# PRM_PER register map
Vendor: Texas Instruments
Peripheral module from a debugger description file (folder am437x).
Registers are 32-bit, access per field, no defined reset value unless marked. A register's access mark holds for its fields unless they carry their own. Offsets are as the file gives them; lines under a group give offsets from that group; [hi:lo] are bit positions; {n}, {i} and the like mark numbered series; 'fields as' and 'values as' point back to an identical list; <NAME> marks a mode.

## PRM_PER
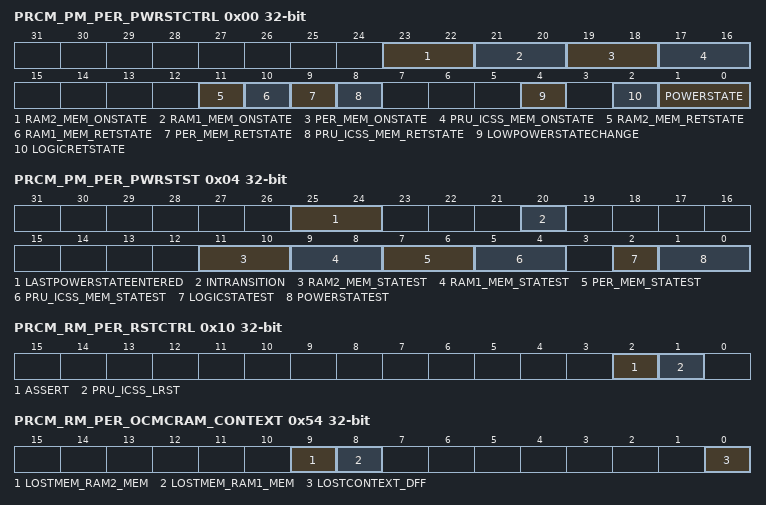
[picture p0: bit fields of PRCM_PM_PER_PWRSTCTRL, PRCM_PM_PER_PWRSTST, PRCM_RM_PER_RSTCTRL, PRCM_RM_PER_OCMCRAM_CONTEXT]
0x00 PRCM_PM_PER_PWRSTCTRL — Controls the power state of PER power domain
  [23:22] RAM2_MEM_ONSTATE ro — OCMC RAM Group 2 (Last 192KB) memory on state
    3=en_1_0x3 (Memory is ON)
  [21:20] RAM1_MEM_ONSTATE ro — OCMC RAM Group 1 (First 64KB) memory on state
    3=en_1_0x3 (Memory is ON)
  [19:18] PER_MEM_ONSTATE ro — Other memories in PER Domain ON state
    3=en_1_0x3 (Memory is ON)
  [17:16] PRU_ICSS_MEM_ONSTATE ro — PRU-ICSS memory ON state
    3=en_1_0x3 (Memory is ON)
  [11] RAM2_MEM_RETSTATE rw — RAM2_MEM[OCMC RAM Group 2 (Last 192KB)] bank state when domain is retention.
    1=en_2_0x1 (Memory is retained when domain is in RETENTION state.); 0=en_1_0x0 (Memory is off when the domain is in the RETENTION state.)
  [10] RAM1_MEM_RETSTATE rw — RAM1_MEM[OCMC RAM Group 1 (First 64KB)] bank state when domain is retention.
    values as RAM2_MEM_RETSTATE
  [9] PER_MEM_RETSTATE rw — PER_MEM bank state when domain is retention.
    values as RAM2_MEM_RETSTATE
  [8] PRU_ICSS_MEM_RETSTATE rw — PRU-ICSS bank state when domain is retention.
    values as RAM2_MEM_RETSTATE
  [4] LOWPOWERSTATECHANGE rw — Power state change request when domain has already performed a sleep transition. [[br]]Allows going into deeper low power state without waking up the power domain.
    1=en_2_0x1 (Request a low power state change. This bit is automatically cleared when the power state is effectively changed or when power state is ON.); 0=en_1_0x0 (Do not request a low power state change.)
  [2] LOGICRETSTATE rw — Logic state when power domain is RETENTION
    1=en_2_0x1 (Whole logic is retained when domain is in RETENTION state.); 0=en_1_0x0 (Only retention registers are retained and remaing logic is off when the domain is in RETENTION state.)
  [1:0] POWERSTATE rw — PER domain power state control
    3=en_4_0x3 (ON State); 2=en_3_0x2 (RESERVED); 1=en_2_0x1 (RETENTION state); 0=en_1_0x0 (OFF State)
0x04 PRCM_PM_PER_PWRSTST — This register provides a status on the current PER power domain state. [warm reset insensitive]
  [25:24] LASTPOWERSTATEENTERED rw — Last low power state entered. [[br]]Set to 0x3 upon write of the same only. [[br]]This register is intended for debug purpose only.
    3=en_4_0x3 (Power domain was previously ON-ACTIVE); 2=en_3_0x2 (Power domain was previously ON-INACTIVE); 1=en_2_0x1 (Power domain was previously in RETENTION); 0=en_1_0x0 (Power domain was previously OFF)
  [20] INTRANSITION ro — Domain transition status
    1=en_2_0x1 (Power domain transition is in progress.); 0=en_1_0x0 (No on-going transition on power domain)
  [11:10] RAM2_MEM_STATEST ro — OCMC RAM Group 1 (Last 192KB) memory state status
    3=en_4_0x3 (Memory is ON); 2=en_3_0x2 (Reserved); 1=en_2_0x1 (Memory is in RETENTION.); 0=en_1_0x0 (Memory is OFF)
  [9:8] RAM1_MEM_STATEST ro — OCMC RAM Group 1 (First 64KB) memory state status
    values as RAM2_MEM_STATEST
  [7:6] PER_MEM_STATEST ro — PER domain memory state status
    values as RAM2_MEM_STATEST
  [5:4] PRU_ICSS_MEM_STATEST ro — PRU-ICSS memory state status
    values as RAM2_MEM_STATEST
  [2] LOGICSTATEST ro — Logic state status
    1=en_2_0x1 (Logic in domain is ON); 0=en_1_0x0 (Logic in domain is OFF)
  [1:0] POWERSTATEST ro — Current Power State Status
    3=en_3_0x3 (ON State); 1=en_2_0x1 (RETENTION state); 0=en_1_0x0 (OFF State)
0x10 PRCM_RM_PER_RSTCTRL — This register controls the release of the PER Domain resets.
  [2] ASSERT ro
  [1] PRU_ICSS_LRST rw — PER domain PRU-ICSS local reset control
    1=en_2_0x1 (Reset is asserted for the PRU-ICSS); 0=en_1_0x0 (Reset is cleared for the PRU-ICSS)
0x14 PRCM_RM_PER_RSTST — This register logs the different reset sources of the PER domain. Each bit is set upon release of the domain reset signal. Must be cleared by software. [warm reset insensitive]
  [0] PRU_ICSS_LRST rw — PRU-ICSS Processor software reset status.
    1=en_2_0x1 (PRU-ICSS Processor has been reset upon SW reset); 0=en_1_0x0 (No reset)
0x24 PRCM_RM_PER_L3_CONTEXT — This register contains dedicated L3 module context statuses. [warm reset insensitive]
  [0] LOSTCONTEXT_DFF rw — Specify if DFF-based context has been lost due to a previous power transition or other reset source. [[br]](set upon assertion of PER_DOM_RST signal)
    1=en_2_0x1 (Context has been lost); 0=en_1_0x0 (Context has been maintained)
0x44 PRCM_RM_PER_L3_INSTR_CONTEXT — This register contains dedicated L3_INSTR module context statuses. [warm reset insensitive]
  fields as PRCM_RM_PER_L3_CONTEXT
0x54 PRCM_RM_PER_OCMCRAM_CONTEXT — This register contains dedicated OCMCRAM module context statuses. [warm reset insensitive]
  [all] fields
    values as PRCM_RM_PER_L3_CONTEXT.LOSTCONTEXT_DFF
  [9] LOSTMEM_RAM2_MEM rw — Specify if memory-based context in RAM2_MEM memory bank has been lost due to a previous power transition or other reset source.
  [8] LOSTMEM_RAM1_MEM rw — Specify if memory-based context in RAM1_MEM memory bank has been lost due to a previous power transition or other reset source.
  [0] LOSTCONTEXT_DFF rw — Specify if DFF-based context has been lost due to a previous power transition or other reset source. [[br]](set upon assertion of PER_DOM_RST signal)
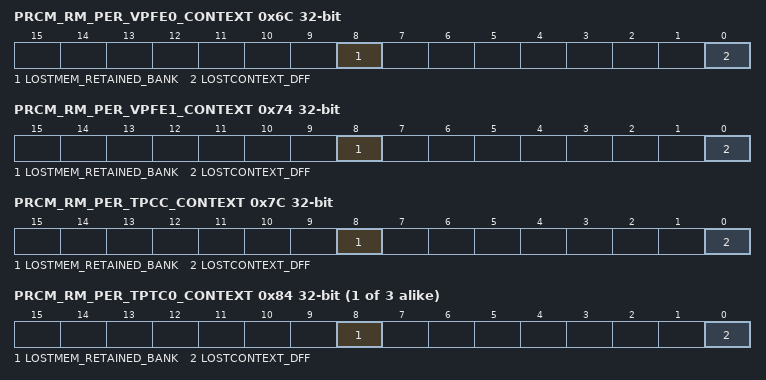
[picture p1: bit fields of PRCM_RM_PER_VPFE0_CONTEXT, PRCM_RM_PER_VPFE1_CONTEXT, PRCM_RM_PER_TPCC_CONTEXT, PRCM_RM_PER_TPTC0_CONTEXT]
0x6C PRCM_RM_PER_VPFE0_CONTEXT — This register contains dedicated VPFE0 module context statuses. [warm reset insensitive]
  [8] LOSTMEM_RETAINED_BANK rw — Specify if memory-based context in RETAINED_BANK memory bank has been lost due to a previous power transition or other reset source.
    values as PRCM_RM_PER_L3_CONTEXT.LOSTCONTEXT_DFF
  [0] LOSTCONTEXT_DFF rw — Specify if DFF-based context has been lost due to a previous power transition or other reset source. [[br]](set upon assertion of PER_DOM_RST signal)
    values as PRCM_RM_PER_L3_CONTEXT.LOSTCONTEXT_DFF
0x74 PRCM_RM_PER_VPFE1_CONTEXT — This register contains dedicated VPFE1 module context statuses. [warm reset insensitive]
  fields as PRCM_RM_PER_VPFE0_CONTEXT
0x7C PRCM_RM_PER_TPCC_CONTEXT — This register contains dedicated TPCC module context statuses. [warm reset insensitive]
  fields as PRCM_RM_PER_VPFE0_CONTEXT
{0x84+8i} PRCM_RM_PER_TPTC{i}_CONTEXT (i=0..2) — This register contains dedicated TPTC{i} module context statuses. [warm reset insensitive]
  fields as PRCM_RM_PER_VPFE0_CONTEXT
0x9C PRCM_RM_PER_DLL_AGING_CONTEXT — This register contains dedicated DLL_AGING module context statuses. [warm reset insensitive]
  fields as PRCM_RM_PER_L3_CONTEXT
0xA4 PRCM_RM_PER_L4HS_CONTEXT — This register contains dedicated L4HS module context statuses. [warm reset insensitive]
  fields as PRCM_RM_PER_L3_CONTEXT
0x224 PRCM_RM_PER_GPMC_CONTEXT — This register contains dedicated GPMC module context statuses. [warm reset insensitive]
  fields as PRCM_RM_PER_L3_CONTEXT
0x234 PRCM_RM_PER_ADC1_CONTEXT — This register contains dedicated ADC1 module context statuses. [warm reset insensitive]
  fields as PRCM_RM_PER_L3_CONTEXT
0x23C PRCM_RM_PER_MCASP0_CONTEXT — This register contains dedicated MCASP0 module context statuses. [warm reset insensitive]
  fields as PRCM_RM_PER_L3_CONTEXT
0x244 PRCM_RM_PER_MCASP1_CONTEXT — This register contains dedicated MCASP1 module context statuses. [warm reset insensitive]
  fields as PRCM_RM_PER_L3_CONTEXT
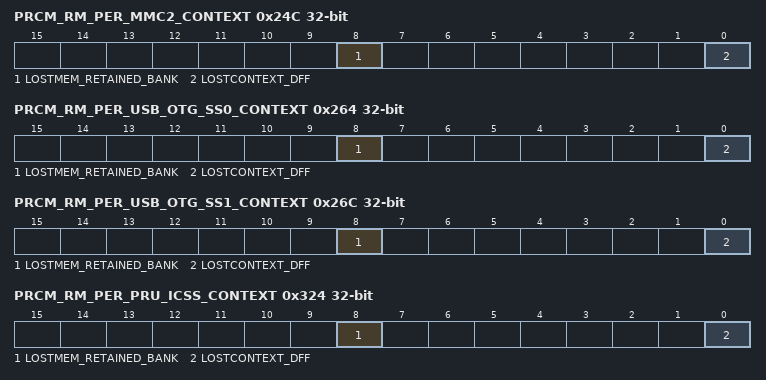
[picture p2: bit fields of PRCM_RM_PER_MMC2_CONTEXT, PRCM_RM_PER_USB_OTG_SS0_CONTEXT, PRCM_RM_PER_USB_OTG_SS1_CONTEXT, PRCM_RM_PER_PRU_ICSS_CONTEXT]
0x24C PRCM_RM_PER_MMC2_CONTEXT — This register contains dedicated MMC2 module context statuses. [warm reset insensitive]
  fields as PRCM_RM_PER_VPFE0_CONTEXT
0x25C PRCM_RM_PER_QSPI_CONTEXT — This register contains dedicated QSPI module context statuses. [warm reset insensitive]
  fields as PRCM_RM_PER_L3_CONTEXT
0x264 PRCM_RM_PER_USB_OTG_SS0_CONTEXT — This register contains dedicated USB_OTG0 context statuses. [warm reset insensitive]
  [8] LOSTMEM_RETAINED_BANK rw — Specify if memory-based context in _BANK1 memory bank has been lost due to a previous power transition or other reset source.
    values as PRCM_RM_PER_L3_CONTEXT.LOSTCONTEXT_DFF
  [0] LOSTCONTEXT_DFF rw — Specify if DFF-based context has been lost due to a previous power transition or other reset source. [[br]](set upon assertion of PER_DOM_RST signal)
    values as PRCM_RM_PER_L3_CONTEXT.LOSTCONTEXT_DFF
0x26C PRCM_RM_PER_USB_OTG_SS1_CONTEXT — This register contains dedicated USB_OTG0 context statuses. [warm reset insensitive]
  fields as PRCM_RM_PER_USB_OTG_SS0_CONTEXT
0x324 PRCM_RM_PER_PRU_ICSS_CONTEXT — This register contains dedicated ICSS module context statuses. [warm reset insensitive]
  fields as PRCM_RM_PER_VPFE0_CONTEXT
0x424 PRCM_RM_PER_L4LS_CONTEXT — This register contains dedicated L4LS module context statuses. [warm reset insensitive]
  fields as PRCM_RM_PER_L3_CONTEXT
0x42C PRCM_RM_PER_DCAN0_CONTEXT — This register contains dedicated DCAN0 module context statuses. [warm reset insensitive]
  fields as PRCM_RM_PER_L3_CONTEXT
0x434 PRCM_RM_PER_DCAN1_CONTEXT — This register contains dedicated DCAN1 module context statuses. [warm reset insensitive]
  fields as PRCM_RM_PER_L3_CONTEXT
{0x43C+8i} PRCM_RM_PER_PWMSS{i}_CONTEXT (i=0..5) — This register contains dedicated PWMSS{i} module context statuses. [warm reset insensitive]
  fields as PRCM_RM_PER_L3_CONTEXT
0x46C PRCM_RM_PER_ELM_CONTEXT — This register contains dedicated ELM module context statuses. [warm reset insensitive]
  fields as PRCM_RM_PER_L3_CONTEXT
{0x474+8i} PRCM_RM_PER_GPIO{i}_CONTEXT (i=1..5) — This register contains dedicated GPIO{i} module context statuses. [warm reset insensitive]
  fields as PRCM_RM_PER_L3_CONTEXT
0x4A4 PRCM_RM_PER_HDQ1W_CONTEXT — This register contains dedicated HDQ1W module context statuses. [warm reset insensitive]
  fields as PRCM_RM_PER_L3_CONTEXT
0x4AC PRCM_RM_PER_I2C1_CONTEXT — This register contains dedicated I2C1 module context statuses. [warm reset insensitive]
  fields as PRCM_RM_PER_L3_CONTEXT
0x4B4 PRCM_RM_PER_I2C2_CONTEXT — This register contains dedicated I2C2 module context statuses. [warm reset insensitive]
  fields as PRCM_RM_PER_L3_CONTEXT
0x4BC PRCM_RM_PER_MAILBOX0_CONTEXT — This register contains dedicated MAILBOX0 module context statuses. [warm reset insensitive]
  fields as PRCM_RM_PER_L3_CONTEXT
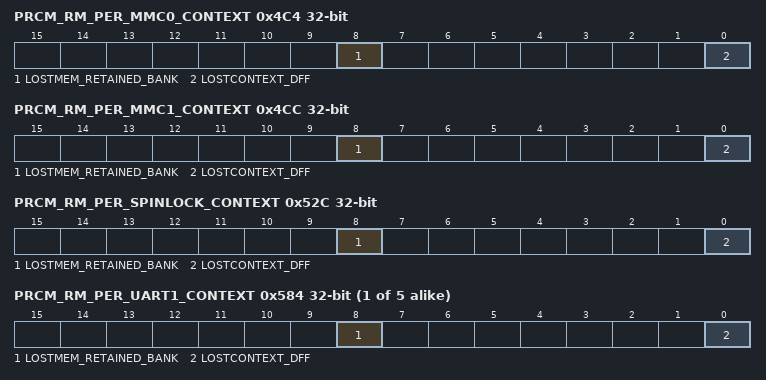
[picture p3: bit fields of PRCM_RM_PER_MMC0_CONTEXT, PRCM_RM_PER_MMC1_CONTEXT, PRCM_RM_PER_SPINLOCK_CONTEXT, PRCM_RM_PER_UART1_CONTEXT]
0x4C4 PRCM_RM_PER_MMC0_CONTEXT — This register contains dedicated MMC0 module context statuses. [warm reset insensitive]
  fields as PRCM_RM_PER_VPFE0_CONTEXT
0x4CC PRCM_RM_PER_MMC1_CONTEXT — This register contains dedicated MMC1 module context statuses. [warm reset insensitive]
  fields as PRCM_RM_PER_VPFE0_CONTEXT
{0x504+8i} PRCM_RM_PER_SPI{i}_CONTEXT (i=0..4) — This register contains dedicated SPI{i} module context statuses. [warm reset insensitive]
  fields as PRCM_RM_PER_L3_CONTEXT
0x52C PRCM_RM_PER_SPINLOCK_CONTEXT — This register contains dedicated SPINLOCK module context statuses. [warm reset insensitive]
  fields as PRCM_RM_PER_VPFE0_CONTEXT
{0x524+8i} PRCM_RM_PER_TIMER{i}_CONTEXT (i=2..11) — This register contains dedicated TIMER{i} module context statuses. [warm reset insensitive]
  fields as PRCM_RM_PER_L3_CONTEXT
{0x57C+8i} PRCM_RM_PER_UART{i}_CONTEXT (i=1..5) — This register contains dedicated UART{i} module context statuses. [warm reset insensitive]
  fields as PRCM_RM_PER_VPFE0_CONTEXT
0x5BC PRCM_RM_PER_USBPHYOCP2SCP0_CONTEXT — This register contains dedicated USBPHYOCP2SCP0 context statuses. [warm reset insensitive]
  [0] LOSTCONTEXT_DFF rw — Specify if DFF-based context has been lost due to a previous power transition or other reset source. [[br]](set upon assertion of L3_INIT_RST signal)
    values as PRCM_RM_PER_L3_CONTEXT.LOSTCONTEXT_DFF
0x5C4 PRCM_RM_PER_USBPHYOCP2SCP1_CONTEXT — This register contains dedicated USBPHYOCP2SCP0 context statuses. [warm reset insensitive]
  fields as PRCM_RM_PER_USBPHYOCP2SCP0_CONTEXT
0x724 PRCM_RM_PER_EMIF_CONTEXT — This register contains dedicated EMIF module context statuses. [warm reset insensitive]
  fields as PRCM_RM_PER_L3_CONTEXT
0x72C PRCM_RM_PER_DLL_CONTEXT — This register contains dedicated DLL module context statuses. [warm reset insensitive]
  fields as PRCM_RM_PER_L3_CONTEXT
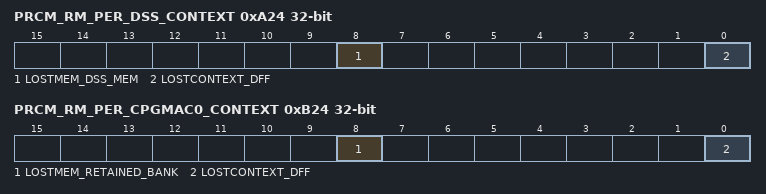
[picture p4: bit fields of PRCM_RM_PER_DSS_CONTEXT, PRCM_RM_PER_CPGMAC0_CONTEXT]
0xA24 PRCM_RM_PER_DSS_CONTEXT — This register contains dedicated DSS module context statuses. [warm reset insensitive]
  [8] LOSTMEM_DSS_MEM rw — Specify if memory-based context in RETAINED_BANK memory bank has been lost due to a previous power transition or other reset source.
    values as PRCM_RM_PER_L3_CONTEXT.LOSTCONTEXT_DFF
  [0] LOSTCONTEXT_DFF rw — Specify if DFF-based context has been lost due to a previous power transition or other reset source. [[br]](set upon assertion of PER_DOM_RST signal)
    values as PRCM_RM_PER_L3_CONTEXT.LOSTCONTEXT_DFF
0xB24 PRCM_RM_PER_CPGMAC0_CONTEXT — This register contains dedicated CPGMAC0 module context statuses. [warm reset insensitive]
  fields as PRCM_RM_PER_VPFE0_CONTEXT
0xC24 PRCM_RM_PER_OCPWP_CONTEXT — This register contains dedicated OCPWP module context statuses. [warm reset insensitive]
  fields as PRCM_RM_PER_L3_CONTEXT
